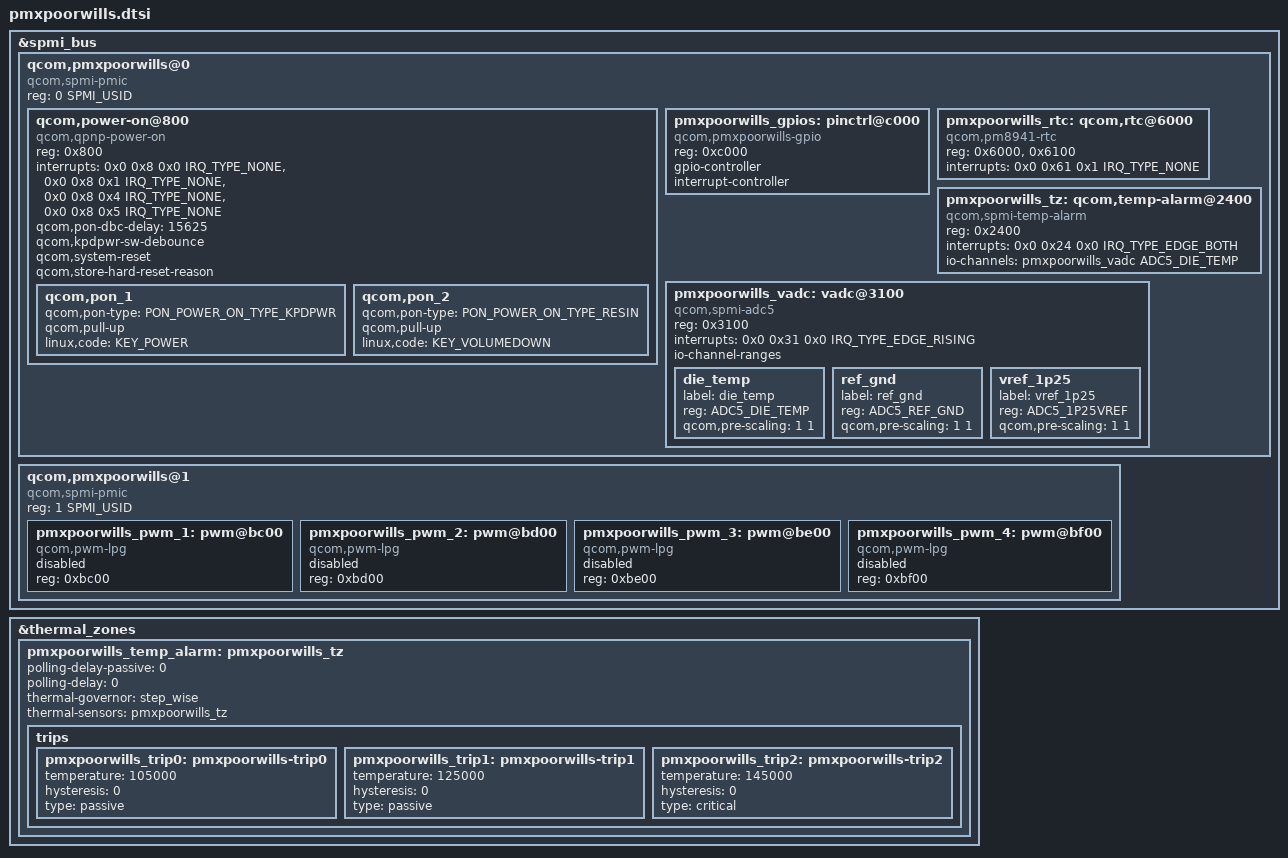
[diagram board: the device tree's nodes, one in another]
#include <dt-bindings/clock/qcom,rpmh.h>
#include <dt-bindings/iio/qcom,spmi-vadc.h>
#include <dt-bindings/input/input.h>
#include <dt-bindings/input/qcom,qpnp-power-on.h>
#include <dt-bindings/interrupt-controller/irq.h>
#include <dt-bindings/spmi/spmi.h>

&spmi_bus {
	qcom,pmxpoorwills@0 {
		compatible = "qcom,spmi-pmic";
		reg = <0 SPMI_USID>;
		#address-cells = <1>;
		#size-cells = <0>;

		qcom,power-on@800 {
			compatible = "qcom,qpnp-power-on";
			reg = <0x800>;
			interrupts = <0x0 0x8 0x0 IRQ_TYPE_NONE>,
				     <0x0 0x8 0x1 IRQ_TYPE_NONE>,
				     <0x0 0x8 0x4 IRQ_TYPE_NONE>,
				     <0x0 0x8 0x5 IRQ_TYPE_NONE>;
			interrupt-names = "kpdpwr", "resin",
					"resin-bark", "kpdpwr-resin-bark";
			qcom,pon-dbc-delay = <15625>;
			qcom,kpdpwr-sw-debounce;
			qcom,system-reset;
			qcom,store-hard-reset-reason;

			qcom,pon_1 {
				qcom,pon-type = <PON_POWER_ON_TYPE_KPDPWR>;
				qcom,pull-up;
				linux,code = <KEY_POWER>;
			};

			qcom,pon_2 {
				qcom,pon-type = <PON_POWER_ON_TYPE_RESIN>;
				qcom,pull-up;
				linux,code = <KEY_VOLUMEDOWN>;
			};
		};

		pmxpoorwills_gpios: pinctrl@c000 {
			compatible = "qcom,pmxpoorwills-gpio";
			reg = <0xc000>;
			gpio-controller;
			#gpio-cells = <2>;
			interrupt-controller;
			#interrupt-cells = <2>;
		};

		pmxpoorwills_rtc: qcom,rtc@6000 {
			compatible = "qcom,pm8941-rtc";
			reg = <0x6000>, <0x6100>;
			reg-names = "rtc", "alarm";
			interrupts = <0x0 0x61 0x1 IRQ_TYPE_NONE>;
		};

		pmxpoorwills_tz: qcom,temp-alarm@2400 {
			compatible = "qcom,spmi-temp-alarm";
			reg = <0x2400>;
			interrupts = <0x0 0x24 0x0 IRQ_TYPE_EDGE_BOTH>;
			io-channels = <&pmxpoorwills_vadc ADC5_DIE_TEMP>;
			io-channel-names = "thermal";
			#thermal-sensor-cells = <0>;
		};

		pmxpoorwills_vadc: vadc@3100 {
			compatible = "qcom,spmi-adc5";
			reg = <0x3100>;
			#address-cells = <1>;
			#size-cells = <0>;
			interrupts = <0x0 0x31 0x0 IRQ_TYPE_EDGE_RISING>;
			interrupt-names = "eoc-int-en-set";
			#io-channel-cells = <1>;
			io-channel-ranges;

			die_temp {
				label = "die_temp";
				reg = <ADC5_DIE_TEMP>;
				qcom,pre-scaling = <1 1>;
			};

			ref_gnd {
				label = "ref_gnd";
				reg = <ADC5_REF_GND>;
				qcom,pre-scaling = <1 1>;
			};

			vref_1p25 {
				label = "vref_1p25";
				reg = <ADC5_1P25VREF>;
				qcom,pre-scaling = <1 1>;
			};
		};
	};

	qcom,pmxpoorwills@1 {
		compatible ="qcom,spmi-pmic";
		reg = <1 SPMI_USID>;
		#address-cells = <1>;
		#size-cells = <0>;

		pmxpoorwills_pwm_1: pwm@bc00 {
			compatible = "qcom,pwm-lpg";
			reg = <0xbc00>;
			reg-names = "lpg-base";
			#pwm-cells = <2>;
			status = "disabled";
		};

		pmxpoorwills_pwm_2: pwm@bd00 {
			compatible = "qcom,pwm-lpg";
			reg = <0xbd00>;
			reg-names = "lpg-base";
			#pwm-cells = <2>;
			status = "disabled";
		};

		pmxpoorwills_pwm_3: pwm@be00 {
			compatible = "qcom,pwm-lpg";
			reg = <0xbe00>;
			reg-names = "lpg-base";
			#pwm-cells = <2>;
			status = "disabled";
		};

		pmxpoorwills_pwm_4: pwm@bf00 {
			compatible = "qcom,pwm-lpg";
			reg = <0xbf00>;
			reg-names = "lpg-base";
			#pwm-cells = <2>;
			status = "disabled";
		};
	};
};

&thermal_zones {
	pmxpoorwills_temp_alarm: pmxpoorwills_tz {
		polling-delay-passive = <0>;
		polling-delay = <0>;
		thermal-governor = "step_wise";
		thermal-sensors = <&pmxpoorwills_tz>;

		trips {
			pmxpoorwills_trip0: pmxpoorwills-trip0 {
				temperature = <105000>;
				hysteresis = <0>;
				type = "passive";
			};

			pmxpoorwills_trip1: pmxpoorwills-trip1 {
				temperature = <125000>;
				hysteresis = <0>;
				type = "passive";
			};

			pmxpoorwills_trip2: pmxpoorwills-trip2 {
				temperature = <145000>;
				hysteresis = <0>;
				type = "critical";
			};
		};
	};
};
